# SN32F240 register map
Vendor: SONiX Technology Co., Ltd.; Series: SN32F200; File version: 2.0
CPU: CM0 r0p0, little endian, no MPU, no FPU, 2 interrupt priority bits
Registers are 32-bit, read-write, reset 0x0 unless marked. A register's access mark holds for its fields unless they carry their own. Offsets are from the block's base; [hi:lo] are bit positions.

## SN_SYS0 — System Control Registers
Base 0x40060000
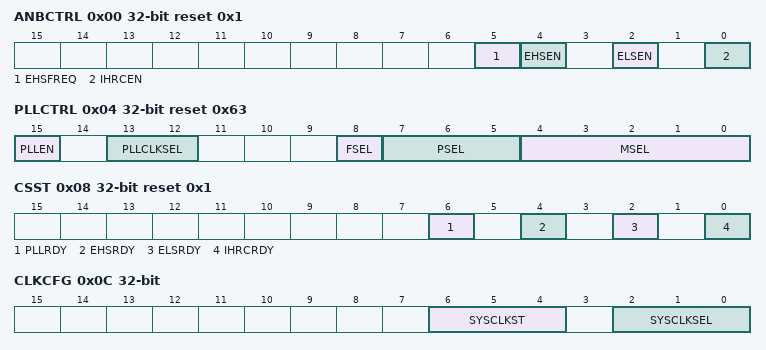
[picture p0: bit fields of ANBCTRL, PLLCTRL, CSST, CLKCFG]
0x00 ANBCTRL reset 0x1 — Offset:0x00 Analog Block Control Register
  [5] EHSFREQ — EHS XTAL frequency range
    0=Low (Less equal than 12MHz); 1=High (Greater than 12MHz)
  [4] EHSEN — EHS XTAL enable
    0=Disable EHS Xtal; 1=Enable EHS Xtal
  [2] ELSEN — ELS XTAL enable
    0=Disable ELS Xtal; 1=Enable ELS Xtal
  [0] IHRCEN — IHRC enable
    0=Disable IHRC; 1=Enable IHRC
0x04 PLLCTRL reset 0x63 — Offset:0x04 PLL Control Register
  [15] PLLEN — PLL enable
    0=Disable PLL; 1=Enable PLL
  [13:12] PLLCLKSEL — PLL clock source
    0=IHRC (12MHz); 1=EHS XTAL (10MHz~25MHz)
  [8] FSEL — F=POWER(2, FSEL)
    0=F=1; 1=F=2
  [7:5] PSEL — P=PSEL*2
    3=011b (P=6); 4=100b (P=8); 5=101b (P=10); 6=110b (P=12); 7=111b (P=14)
  [4:0] MSEL — M: 3~31
0x08 CSST ro reset 0x1 — Offset:0x08 Clock Source Status Register
  [6] PLLRDY — PLL ready flag
    0=PLL is Not locked; 1=PLL is locked
  [4] EHSRDY — EHS XTAL ready flag
    0=EHS Xtal is Not Ready; 1=EHS Xtal is Ready
  [2] ELSRDY — ELS XTAL ready flag
    0=ELS Xtal is Not Ready; 1=ELS Xtal is Ready
  [0] IHRCRDY — IHRC ready flag
    0=IHRC is Not Ready; 1=IHRC is Ready
0x0C CLKCFG — Offset:0x0C System Clock Configuration Register
  [6:4] SYSCLKST ro — System clock switch status
    0=IHRC (IHRC is used as system clock); 1=ILRC (ILRC is used as system clock); 2=EHS XTAL (EHS XTAL is used as system clock); 3=ELS XTAL (ELS XTAL is used as system clock); 4=PLL (PLL output is used as system clock)
  [2:0] SYSCLKSEL — System clock source selection
    0=IHRC (IHRC is system clock); 1=ILRC (ILRC is system clock); 2=EHS XTAL (EHS Xtal is system clock); 3=ELS XTAL (ELS Xtal is system clock); 4=PLL Output (PLL is system clock)
0x10 AHBCP — Offset:0x10 AHB Clock Prescale Register
  [3:0] AHBPRE — AHB clock source prescaler
    0=0000b (FAHB=FSYSCLK/1); 1=0001b (FAHB=FSYSCLK/2); 2=0010b (FAHB=FSYSCLK/4); 3=0011b (FAHB=FSYSCLK/8); 4=0100b (FAHB=FSYSCLK/16); 5=0101b (FAHB=FSYSCLK/32); 6=0110b (FAHB=FSYSCLK/64); 7=0111b (FAHB=FSYSCLK/128); 8=1000b (FAHB=FSYSCLK/256); 9=1001b (FAHB=FSYSCLK/512)
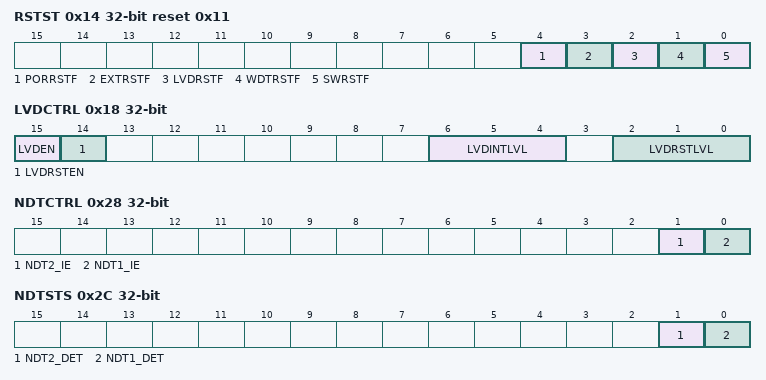
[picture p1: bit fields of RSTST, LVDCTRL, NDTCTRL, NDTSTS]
0x14 RSTST reset 0x11 — Offset:0x14 System Reset Status Register
  [4] PORRSTF — POR reset flag
    0=No POR occurred; 1=POR occurred
  [3] EXTRSTF — External reset flag
    0=No Extenral reset occurred; 1=External reset occurred
  [2] LVDRSTF — LVD reset flag
    0=No LVD reset occurred; 1=LVD reset occurred
  [1] WDTRSTF — WDT reset flag
    0=No WDT reset occurred; 1=WDT reset occurred
  [0] SWRSTF — Software reset flag
    0=No SW reset occurred; 1=SW reset occurred
0x18 LVDCTRL — Offset:0x18 LVD Control Register
  [15] LVDEN — LVD enable
    0=Diable (Disable LVD); 1=Enable LVD
  [14] LVDRSTEN — LVD Reset enable
    0=Diable (Disable LVD reset); 1=Enable LVD reset
  [6:4] LVDINTLVL — LVD interrupt level
    0=1.80V (LVD interrupt threshold is 1.80V); 1=2.00V (LVD interrupt threshold is 2.00V); 2=2.40V (LVD interrupt threshold is 2.40V); 3=2.70V (LVD interrupt threshold is 2.70V); 4=3.00V (LVD interrupt threshold is 3.00V); 5=3.60V (LVD interrupt threshold is 3.60V)
  [2:0] LVDRSTLVL — LVD reset level
    0=1.80V (LVD reset threshold is 1.80V); 1=2.00V (LVD reset threshold is 2.00V); 2=2.40V (LVD reset threshold is 2.40V); 3=2.70V (LVD reset threshold is 2.70V); 4=3.00V (LVD reset threshold is 3.00V); 5=3.60V (LVD reset threshold is 3.60V)
0x1C EXRSTCTRL reset 0x1 — Offset:0x1C External Reset Pin Control Register
  [0] RESETDIS — External reset pin disable
    0=Enable (P3.10 acts as External Reset pin); 1=Disable (P3.10 acts as GPIO pin)
0x20 SWDCTRL — Offset:0x20 SWD Pin Control Register
  [0] SWDDIS — SWD pin disable
    0=Enable SWD pins; 1=Disable SWD pins
0x28 NDTCTRL — Offset:0x28 Noise Detect Control Register
  [1] NDT2_IE — NDT for VDD interrupt enable bit
    0=Disable; 1=Enable
  [0] NDT1_IE — NDT for Vcore interrupt enable bit
    0=Disable; 1=Enable
0x2C NDTSTS — Offset:0x2C Noise Detect Status Register
  [1] NDT2_DET — Power noise status of NDT2
    0=No (No power noise is detected); 1=Detected (Power noise is detected by NDT5V IP)
  [0] NDT1_DET — Power noise status of NDT1
    0=No (No power noise is detected); 1=Detected (Power noise is detected by NDT18 IP)
0x30 ANTIEFT — Offset:0x30 Anti-EFT Ability Control Register
  [2:0] AEFT — Anti-EFT ability
    0=Disable; 1=Low; 3=Medium; 4=Strong
